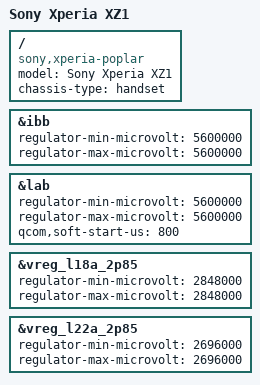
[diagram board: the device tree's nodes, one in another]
// SPDX-License-Identifier: BSD-3-Clause
/*
 * Copyright (c) 2021, AngeloGioacchino Del Regno
 *                     <angelogioacchino.delregno@somainline.org>
 */

/dts-v1/;

#include "msm8998-sony-xperia-yoshino.dtsi"

/ {
	model = "Sony Xperia XZ1";
	compatible = "sony,xperia-poplar", "qcom,msm8998";
	chassis-type = "handset";
};

&ibb {
	regulator-min-microvolt = <5600000>;
	regulator-max-microvolt = <5600000>;
};

&lab {
	regulator-min-microvolt = <5600000>;
	regulator-max-microvolt = <5600000>;
	qcom,soft-start-us = <800>;
};

&vreg_l18a_2p85 {
	/* Note: Round-down from 2850000 to be a multiple of PLDO step-size 8000 */
	regulator-min-microvolt = <2848000>;
	regulator-max-microvolt = <2848000>;
};

&vreg_l22a_2p85 {
	/* Note: Round-down from 2700000 to be a multiple of PLDO step-size 8000 */
	regulator-min-microvolt = <2696000>;
	regulator-max-microvolt = <2696000>;
};
